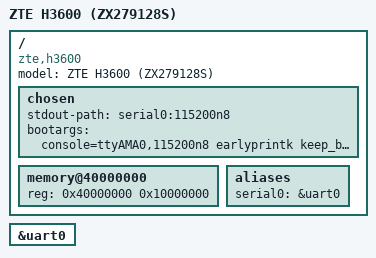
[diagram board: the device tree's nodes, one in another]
// SPDX-License-Identifier: GPL-2.0
/*
 * ZTE H3600 (DIGI Spain) - based on ZX279128S SoC
 * 256 MiB DDR @ 0x40000000
 * 128 MiB ESMT SPI NAND F50L1G41LB
 */

/dts-v1/;

#include "zx279128s.dtsi"

/ {
	model = "ZTE H3600 (ZX279128S)";
	compatible = "zte,h3600", "zte,zx279128s";

	chosen {
		stdout-path = "serial0:115200n8";
		bootargs = "console=ttyAMA0,115200n8 earlyprintk keep_bootcon ignore_loglevel init=/bin/sh";
	};

	memory@40000000 {
		device_type = "memory";
		reg = <0x40000000 0x10000000>;	/* 256 MiB */
	};

	aliases {
		serial0 = &uart0;
	};
};

&uart0 {
	status = "okay";
};
